# MCXA156 register map
Vendor: nxp.com; File version: 1.0
CPU: CM33 r2p0, little endian, no MPU, FPU, VTOR, 3 interrupt priority bits
Registers are 32-bit, read-write, reset 0x0 unless marked. A register's access mark holds for its fields unless they carry their own. Offsets are from the block's base; [hi:lo] are bit positions; {n}, {i} and the like mark numbered series.

## OSTIMER0 — OSTIMER
Base 0x400AD000
0x00 EVTIMERL ro — EVTIMER Low
  [31:0] EVTIMER_COUNT_VALUE
0x04 EVTIMERH ro — EVTIMER High
  [9:0] EVTIMER_COUNT_VALUE
0x08 CAPTURE_L ro — Local Capture Low for CPU
  [31:0] CAPTURE_VALUE — EVTimer Capture Value
0x0C CAPTURE_H ro — Local Capture High for CPU
  [9:0] CAPTURE_VALUE — EVTimer Capture Value
0x10 MATCH_L reset 0xFFFFFFFF — Local Match Low for CPU
  [31:0] MATCH_VALUE — EVTimer Match Value
0x14 MATCH_H reset 0xFFFFFFFF — Local Match High for CPU
  [9:0] MATCH_VALUE — EVTimer Match Value
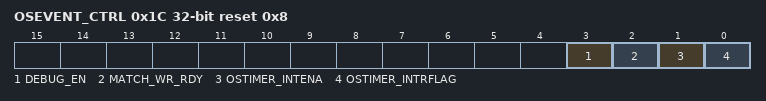
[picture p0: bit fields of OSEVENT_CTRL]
0x1C OSEVENT_CTRL reset 0x8 — OSTIMER Control for CPU
  [3] DEBUG_EN — Debug Enable
    0=DISABLE (Disables); 1=ENABLE (Enables)
  [2] MATCH_WR_RDY ro — EVTimer Match Write Ready
  [1] OSTIMER_INTENA — Interrupt or Wake-Up Request
    0=INTERRUPTS_BLOCKED; 1=INTERRUPTS_ENABLED
  [0] OSTIMER_INTRFLAG write-1-clears — Interrupt Flag

## WAKETIMER0 — WAKEUP_TIMER
Base 0x400AE000
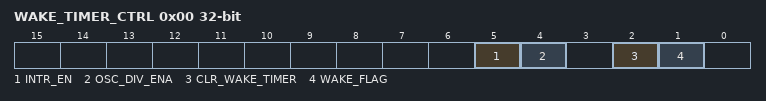
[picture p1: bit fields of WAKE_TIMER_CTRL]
0x00 WAKE_TIMER_CTRL — Wake Timer Control
  [5] INTR_EN — Enable Interrupt
    0=DISABLE (Disabled); 1=ENABLE (Enabled)
  [4] OSC_DIV_ENA — OSC Divide Enable
    0=DISABLE (Disabled); 1=ENABLE (Enabled)
  [2] CLR_WAKE_TIMER wo — Clear Wake Timer
    0=DISABLE (No effect.); 1=ENABLE (Clears the wake timer counter and halts operation until a new count value is loaded.)
  [1] WAKE_FLAG write-1-clears — Wake Timer Status Flag
    0=DISABLE (Wake timer has not timed out.); 1=ENABLE (Wake timer has timed out.)
0x0C WAKE_TIMER_CNT — Wake Timer Counter
  [31:0] WAKE_CNT — Wake Counter

## OPAMP0 — OPAMP
Base 0x400B7000
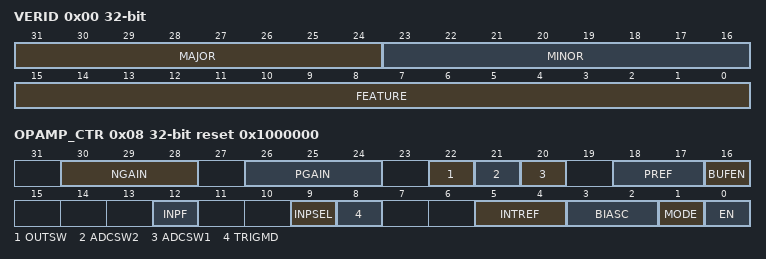
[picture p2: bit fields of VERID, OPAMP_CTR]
0x00 VERID ro — Version ID
  [31:24] MAJOR — Major Version Number
  [23:16] MINOR — Minor Version Number
  [15:0] FEATURE — Feature Specification Number
0x04 PARAM ro reset 0x1 — Parameter
  [0] PGA_FUNCTION — PGA Function Option
    0=CORE_AMP (Core amplifier enabled); 1=PGA (PGA function enabled)
0x08 OPAMP_CTR reset 0x1000000 — OPAMP Control
  [30:28] NGAIN — Negative PGA Selection
    0=BUFFER; 1=G1 (Ngain=1); 2=G2 (Ngain=2); 3=G4 (Ngain=4); 4=G8 (Ngain=8); 5=G16 (Ngain=16); 6=G33 (Ngain=33); 7=G64 (Ngain=64)
  [26:24] PGAIN — Positive PGA Selection
    0=INP1 (Positive input 1 (INP1)); 1=G2 (Pgain=1); 2=G3 (Pgain=2); 3=G5 (Pgain=4); 4=G9 (Pgain=8); 5=G17 (Pgain=16); 6=G34 (Pgain=33); 7=G65 (Pgain=64)
  [22] OUTSW — Output Switch
    0=OFF (OPAMP out to negative gain resistor ladder switch off); 1=ON (OPAMP out to negative gain resistor ladder switch on)
  [21] ADCSW2 — Measure Switch 2
    0=DISABLE (Measure positive gain resistor ladder reference voltage switch off); 1=ENABLE (Measure positive gain resistor ladder reference voltage switch on)
  [20] ADCSW1 — Measure Switch 1
    0=OFF (Measure negative gain resistor ladder voltage switch off); 1=ON (Measure negative gain resistor ladder voltage switch on)
  [18:17] PREF — Positive Reference Voltage Selection
    {v}=Input {v} (v=0..3)
  [16] BUFEN — Reference Buffer
    0=DISABLE (Disables); 1=ENABLE (Enables)
  [12] INPF ro — Positive Input Connection Status
    0=INP0 (Positive input 0 (INP0)); 1=INP1 (Positive input 1 (INP1))
  [9] INPSEL — Positive Input Channel Selection
    0=INP0 (When OPAMP is not in trigger mode, select positive input 0 (INP0)); 1=INP1 (When OPAMP is not in trigger mode, select positive input 1 (INP1))
  [8] TRIGMD — Trigger Mode
    0=DISABLE; 1=ENABLE
  [5:4] INTREF — Provide OPAMP rail to rail voltage selection
    0=VDDA2 (Select OPAMP input rail to rail voltage from 0 to VDD_ANA); 1=VDDA3V (Select OPAMP input rail to rail voltage from 0 to VDD_ANA-0.8V); 2=VSSA3V (Select OPAMP input rail to rail voltage from 0.8V to VDD_ANA); 3=NOT (Not allowed)
  [3:2] BIASC — Bias Current Trim Selection
    0=DEF (Default); 1=INC (Increase current); 2=DEC (Decrease current); 3=FUR_DEC (Further decrease current)
  [1] MODE — Mode Selection
    0=LOW (High performance mode); 1=HIGH (Low power mode)
  [0] EN — OPAMP Enable
    0=DISABLE; 1=ENABLE
